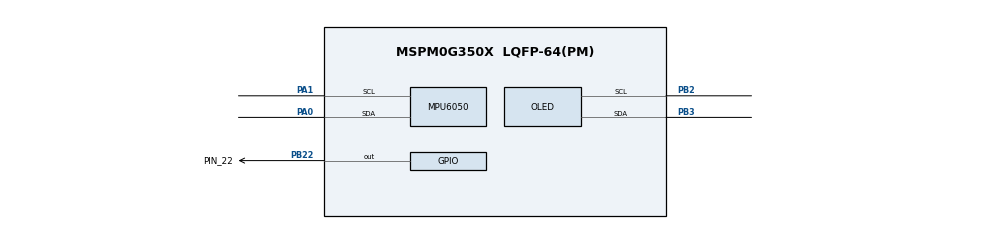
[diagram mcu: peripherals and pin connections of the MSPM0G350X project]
/**
 * @cliArgs --device "MSPM0G350X" --part "Default" --package "LQFP-64(PM)" --product "mspm0_sdk@2.10.00.04"
 * @versions {"tool":"1.26.2+4477"}
 */

const GPIO    = scripting.addModule("/ti/driverlib/GPIO", {}, false);
const GPIO1   = GPIO.addInstance();
const I2C     = scripting.addModule("/ti/driverlib/I2C", {}, false);
const MPU6050 = I2C.addInstance();
const OLED    = I2C.addInstance();
const SYSTICK = scripting.addModule("/ti/driverlib/SYSTICK");
const SYSCTL  = scripting.addModule("/ti/driverlib/SYSCTL");

GPIO1.$name                         = "LED1";
GPIO1.associatedPins[0].$name       = "PIN_22";
GPIO1.associatedPins[0].pin.$assign = "PB22";

MPU6050.$name                         = "MPU6050";
MPU6050.basicEnableController         = true;
MPU6050.basicControllerBusSpeed       = 100000;
MPU6050.advDigitalGlitchFilter        = "CLOCKS_1";
MPU6050.advControllerRXFIFOTRIG       = "BYTES_8";
MPU6050.advControllerTXFIFOTRIG       = "BYTES_7";
MPU6050.enableDMAEvent1               = false;
MPU6050.enableDMAEvent2               = false;
MPU6050.peripheral.sdaPin.$assign     = "PA0";
MPU6050.peripheral.sclPin.$assign     = "PA1";

OLED.$name                         = "OLED";
OLED.basicEnableController         = true;
OLED.basicControllerBusSpeed       = 100000;
OLED.advDigitalGlitchFilter        = "CLOCKS_1";
OLED.advControllerRXFIFOTRIG       = "BYTES_8";
OLED.advControllerTXFIFOTRIG       = "BYTES_7";
OLED.enableDMAEvent1               = false;
OLED.enableDMAEvent2               = false;
OLED.peripheral.sdaPin.$assign     = "PB3";
OLED.peripheral.sclPin.$assign     = "PB2";

SYSTICK.period          = 32000;
SYSTICK.periodEnable    = true;
SYSTICK.systickEnable   = true;
SYSTICK.interruptEnable = true;

const Board = scripting.addModule("/ti/driverlib/Board", {}, false);

SYSCTL.forceDefaultClkConfig = true;
Board.peripheral.$suggestSolution          = "DEBUGSS";
Board.peripheral.swclkPin.$suggestSolution = "PA20";
Board.peripheral.swdioPin.$suggestSolution = "PA19";
SYSCTL.peripheral.$suggestSolution         = "SYSCTL";
MPU6050.peripheral.$suggestSolution        = "I2C0";
OLED.peripheral.$suggestSolution           = "I2C1";
